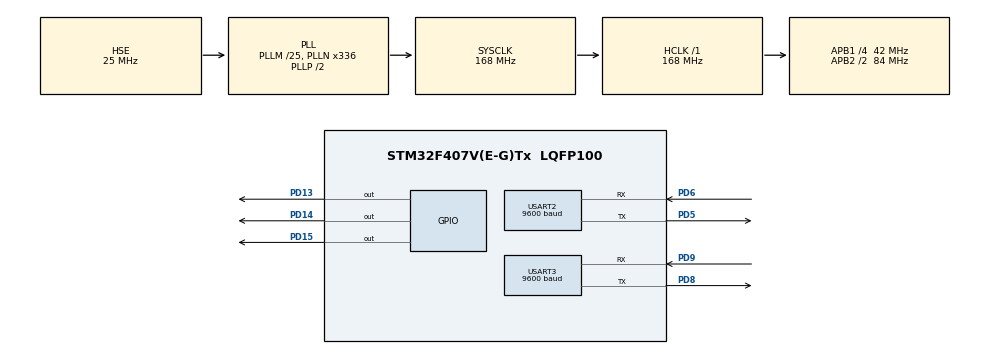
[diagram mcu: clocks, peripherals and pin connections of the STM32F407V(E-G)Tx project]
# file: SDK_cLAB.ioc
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FREERTOS.Tasks01=defaultTask,0,128,StartDefaultTask,Default,NULL,Dynamic,NULL,NULL
IWDG.Prescaler=IWDG_PRESCALER_64
Mcu.Family=STM32F4
Mcu.Name=STM32F407V(E-G)Tx
Mcu.Package=LQFP100
NVIC.PriorityGroup=NVIC_PRIORITYGROUP_4
NVIC.USART2_IRQn=true\:0\:0\:false\:false\:true\:false\:true\:true
NVIC.USART3_IRQn=true\:0\:0\:false\:false\:true\:false\:true\:true
PA13.Mode=JTAG_5_pins
PA13.Signal=SYS_JTMS-SWDIO
PA14.Mode=JTAG_5_pins
PA14.Signal=SYS_JTCK-SWCLK
PA15.Mode=JTAG_5_pins
PA15.Signal=SYS_JTDI
PB3.Mode=JTAG_5_pins
PB3.Signal=SYS_JTDO-SWO
PB4.Mode=JTAG_5_pins
PB4.Signal=SYS_JTRST
PD13.GPIO_Speed=GPIO_SPEED_FREQ_HIGH
PD13.PinState=GPIO_PIN_RESET
PD13.Signal=GPIO_Output
PD14.GPIO_Speed=GPIO_SPEED_FREQ_HIGH
PD14.PinState=GPIO_PIN_RESET
PD14.Signal=GPIO_Output
PD15.GPIO_Speed=GPIO_SPEED_FREQ_HIGH
PD15.Signal=GPIO_Output
PD5.Mode=Asynchronous
PD5.Signal=USART2_TX
PD6.Mode=Asynchronous
PD6.Signal=USART2_RX
PD8.Mode=Asynchronous
PD8.Signal=USART3_TX
PD9.Mode=Asynchronous
PD9.Signal=USART3_RX
PH0-OSC_IN.Mode=HSE-External-Oscillator
PH0-OSC_IN.Signal=RCC_OSC_IN
PH1-OSC_OUT.Mode=HSE-External-Oscillator
PH1-OSC_OUT.Signal=RCC_OSC_OUT
ProjectManager.HeapSize=0x200
ProjectManager.StackSize=0x400
ProjectManager.TargetToolchain=STM32CubeIDE
RCC.48MHZClocksFreq_Value=84000000
RCC.AHBFreq_Value=168000000
RCC.APB1CLKDivider=RCC_HCLK_DIV4
RCC.APB1Freq_Value=42000000
RCC.APB1TimFreq_Value=84000000
RCC.APB2CLKDivider=RCC_HCLK_DIV2
RCC.APB2Freq_Value=84000000
RCC.APB2TimFreq_Value=168000000
RCC.CortexFreq_Value=168000000
RCC.HCLKFreq_Value=168000000
RCC.HSE_VALUE=25000000
RCC.HSI_VALUE=16000000
RCC.LSE_VALUE=32768
RCC.PLLM=25
RCC.PLLN=336
RCC.PLLSourceVirtual=RCC_PLLSOURCE_HSE
RCC.SYSCLKFreq_VALUE=168000000
RCC.SYSCLKSource=RCC_SYSCLKSOURCE_PLLCLK
RCC.VCOOutputFreq_Value=336000000
USART2.BaudRate=9600
USART2.VirtualMode=VM_ASYNC
USART3.BaudRate=9600
USART3.VirtualMode=VM_ASYNC
VP_FREERTOS_VS_CMSIS_V1.Mode=CMSIS_V1
VP_IWDG_VS_IWDG.Mode=IWDG_Activate
VP_RTC_VS_RTC_Activate.Mode=RTC_Enabled
board=custom

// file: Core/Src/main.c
/* USER CODE BEGIN Header */
/**
  ******************************************************************************
  * @file           : main.c
  * @brief          : Main program body
  ******************************************************************************
  * @attention
  *
  * <h2><center>&copy; Copyright (c) 2020 STMicroelectronics.
  * All rights reserved.</center></h2>
  *
  * This software component is licensed by ST under BSD 3-Clause license,
  * the "License"; You may not use this file except in compliance with the
  * License. You may obtain a copy of the License at:
  *                        opensource.org/licenses/BSD-3-Clause
  *
  ******************************************************************************
  */
/* USER CODE END Header */
#include "main.h"
#include "cmsis_os.h"
#include "iwdg.h"
#include "rtc.h"
#include "usart.h"
#include "gpio.h"

/* USER CODE BEGIN Includes */
#include "trace.h"
#include "stdio.h"
/* USER CODE END Includes */

/* USER CODE BEGIN PV */
RTC_TimeTypeDef time;
RTC_DateTypeDef date;
char str_for_date[100];
char str_for_time[100];
uint8_t msg_sending_from_USART3[] = "USART3";
uint8_t msg_receiving_in_USART2[6];
/* USER CODE END PV */

void SystemClock_Config(void);
void MX_FREERTOS_Init(void);

int main(void)
{

  /* MCU Configuration--------------------------------------------------------*/

  /* Reset of all peripherals, Initializes the Flash interface and the Systick. */
  HAL_Init();

  /* Configure the system clock */
  SystemClock_Config();

  /* Initialize all configured peripherals */
  MX_GPIO_Init();
  MX_IWDG_Init();
  MX_USART2_UART_Init();
  MX_USART3_UART_Init();
  MX_RTC_Init();
  /* USER CODE BEGIN 2 */
/*
 * Функция включает прерывания по флагу RXNE, разобраться, что это за флаг
 * и какие еще бывают.
 * В рамках 1-й лабы, раскомментировать ее и перейти в файл stm32f4xx_it.c
 * В обработчике прерываний по USART2, принять и обработать сообщение.
 */
  //__HAL_UART_ENABLE_IT(&huart2, UART_IT_RXNE);

  /* Do not remove this code below */
  MX_TRACE_Init();
  SDK_TRACE_Start();
  /* Do not remove this code from above */
/* Блок работы с UART и функциями обратного вызова ---------------------------------------------------------*/

  /* Блокирующие функции */
  /* HAL_UART_Transmit(&huart3, msg_sending_from_USART3, 6, 50);

  	 HAL_UART_Receive(&huart2, msg_receiving_in_USART2, 6, 50); */

  /* Неблокирующие функции */
  /*HAL_UART_Transmit_IT(&huart3, msg_sending_from_USART3, 6);

  	HAL_UART_Receive_IT(&huart2, msg_receiving_in_USART2, 6); */
/* ---------------------------------------------------------------------------------------------------------*/

/* Тестовый пример работы со светодиодами ------------------------------------------------------------------*/

  /*SDK_TRACE_Timestamp(PRINT, 1);
  SDK_TRACE_Print("%s","LEDs Blink test");
  SDK_TRACE_Timestamp(PRINT, 0);
  HAL_GPIO_TogglePin(GPIOD, GPIO_PIN_15);
  SDK_TRACE_Timestamp(LED3, HAL_GPIO_ReadPin(GPIOD, GPIO_PIN_15));*/
  /* Place your code from here */
  /* Example of using LED tracing */

  /*for (int i = 0; i < 10; i++) {
	  HAL_GPIO_TogglePin(GPIOD, GPIO_PIN_13);
  	  SDK_TRACE_Timestamp(LED1, HAL_GPIO_ReadPin(GPIOD, GPIO_PIN_13));
  	  HAL_GPIO_TogglePin(GPIOD, GPIO_PIN_15);
  	  SDK_TRACE_Timestamp(LED3, HAL_GPIO_ReadPin(GPIOD, GPIO_PIN_15));
  	  HAL_Delay(250);
  }

  HAL_GPIO_WritePin(GPIOD, GPIO_PIN_13, GPIO_PIN_RESET);
  SDK_TRACE_Timestamp(LED1, HAL_GPIO_ReadPin(GPIOD, GPIO_PIN_13));
  HAL_GPIO_WritePin(GPIOD, GPIO_PIN_15, GPIO_PIN_RESET);
  SDK_TRACE_Timestamp(LED3, HAL_GPIO_ReadPin(GPIOD, GPIO_PIN_15));

  SDK_TRACE_Timestamp(PRINT, 1);
  SDK_TRACE_Print("%s","Test passed");
  SDK_TRACE_Timestamp(PRINT, 0);*/

  /* Example of sending debug messages */

  // SDK_TRACE_Print("%s%d%s%X", "Decimal value: ", 255, " Hex value: ", 255);

  /* Place your code before here */
  /* Do not remove this code below */
 // SDK_TRACE_Stop();
  /* Do not remove this code from above */

/*---------------------------------------------------------------------------------------------------------*/

/* Блок работы c RTC --------------------------------------------------------------------------------------*/

  /*SDK_TRACE_Timestamp(PRINT, 0);
HAL_RTC_GetTime(&hrtc, &time, RTC_FORMAT_BCD);
HAL_RTC_GetDate(&hrtc, &date, RTC_FORMAT_BCD);
SDK_TRACE_Timestamp(PRINT, 1);

sprintf(str_for_time, "1: Hour = %d Minutes = %d Seconds = %d", time.Hours, time.Minutes, time.Seconds);
sprintf(str_for_date, "1: WeekDay = %d Date = %d Month = %d Year = %d", date.WeekDay, date.Date, date.Month, date.Year);

SDK_TRACE_Timestamp(PRINT, 0);
SDK_TRACE_Print(str_for_time);
SDK_TRACE_Print(str_for_date);
SDK_TRACE_Timestamp(PRINT, 1);

SDK_TRACE_Stop();*/

/*---------------------------------------------------------------------------------------------------------*/
  /* USER CODE END 2 */

  /* Call init function for freertos objects (in freertos.c) */
  MX_FREERTOS_Init();
  /* Start scheduler */

  //osKernelStart(); // Функция включает планировщик задач FreeRTOS

  /* We should never get here as control is now taken by the scheduler */
  /* Infinite loop */
  while (1)
  {

  }
}

void SystemClock_Config(void)
{
  RCC_OscInitTypeDef RCC_OscInitStruct = {0};
  RCC_ClkInitTypeDef RCC_ClkInitStruct = {0};
  RCC_PeriphCLKInitTypeDef PeriphClkInitStruct = {0};

  /** Configure the main internal regulator output voltage
  */
  __HAL_RCC_PWR_CLK_ENABLE();
  __HAL_PWR_VOLTAGESCALING_CONFIG(PWR_REGULATOR_VOLTAGE_SCALE1);
  /** Initializes the RCC Oscillators according to the specified parameters
  * in the RCC_OscInitTypeDef structure.
  */
  RCC_OscInitStruct.OscillatorType = RCC_OSCILLATORTYPE_LSI|RCC_OSCILLATORTYPE_HSE;
  RCC_OscInitStruct.HSEState = RCC_HSE_ON;
  RCC_OscInitStruct.LSIState = RCC_LSI_ON;
  RCC_OscInitStruct.PLL.PLLState = RCC_PLL_ON;
  RCC_OscInitStruct.PLL.PLLSource = RCC_PLLSOURCE_HSE;
  RCC_OscInitStruct.PLL.PLLM = 25;
  RCC_OscInitStruct.PLL.PLLN = 336;
  RCC_OscInitStruct.PLL.PLLP = RCC_PLLP_DIV2;
  RCC_OscInitStruct.PLL.PLLQ = 4;
  if (HAL_RCC_OscConfig(&RCC_OscInitStruct) != HAL_OK)
  {
    Error_Handler();
  }
  /** Initializes the CPU, AHB and APB buses clocks
  */
  RCC_ClkInitStruct.ClockType = RCC_CLOCKTYPE_HCLK|RCC_CLOCKTYPE_SYSCLK
                              |RCC_CLOCKTYPE_PCLK1|RCC_CLOCKTYPE_PCLK2;
  RCC_ClkInitStruct.SYSCLKSource = RCC_SYSCLKSOURCE_PLLCLK;
  RCC_ClkInitStruct.AHBCLKDivider = RCC_SYSCLK_DIV1;
  RCC_ClkInitStruct.APB1CLKDivider = RCC_HCLK_DIV4;
  RCC_ClkInitStruct.APB2CLKDivider = RCC_HCLK_DIV2;

  if (HAL_RCC_ClockConfig(&RCC_ClkInitStruct, FLASH_LATENCY_5) != HAL_OK)
  {
    Error_Handler();
  }
  PeriphClkInitStruct.PeriphClockSelection = RCC_PERIPHCLK_RTC;
  PeriphClkInitStruct.RTCClockSelection = RCC_RTCCLKSOURCE_LSI;
  if (HAL_RCCEx_PeriphCLKConfig(&PeriphClkInitStruct) != HAL_OK)
  {
    Error_Handler();
  }
}
/*
 * Функции обратного вызова, в рамках 1-й лабораторной,
 * разобраться в принципе их работы.
 */
/* USER CODE BEGIN 4 */
/*void HAL_UART_RxCpltCallback(UART_HandleTypeDef *huart)
{
	if(huart == &huart2){
		//SDK_TRACE_Print("%s", msg_receiving_in_USART2);
		SDK_TRACE_Print("%s", msg_receiving_in_USART2);
		SDK_TRACE_Stop();
	}
}
void HAL_UART_TxCpltCallback(UART_HandleTypeDef *huart)
{
	if(huart == &huart3){
		SDK_TRACE_Print("%s","Callback function");

	}
}*/
/* USER CODE END 4 */

void Error_Handler(void)
{
}

/************************ (C) COPYRIGHT STMicroelectronics *****END OF FILE****/
